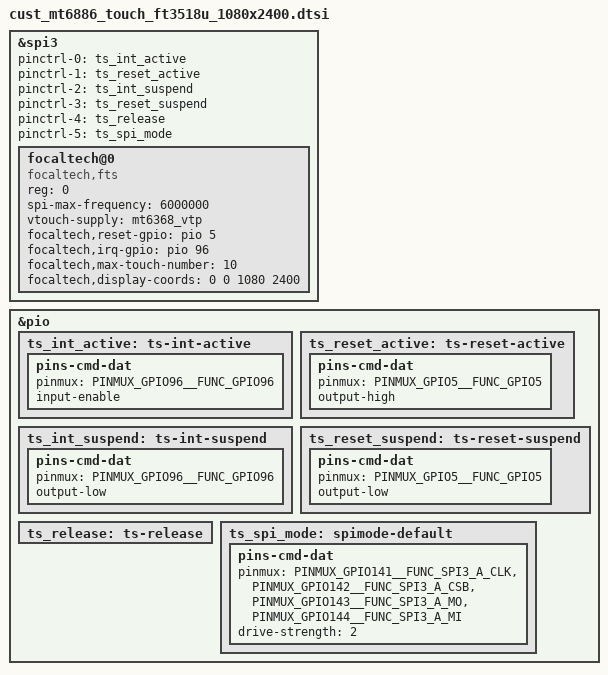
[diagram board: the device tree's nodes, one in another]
// SPDX-License-Identifier: (GPL-2.0 OR MIT)
/*
 * Copyright (C) 2020 MediaTek Inc.
 */

/*TOUCH begin*/
&spi3 {
	status = "okay";
	#address-cells = <1>;
	#size-cells = <0>;
	pinctrl-names = "pmx_ts_int_active", "pmx_ts_rst_active",
		"pmx_ts_int_suspend", "pmx_ts_rst_suspend",
		"pmx_ts_release", "ft3518u_spi_mode";
	pinctrl-0 = <&ts_int_active>;
	pinctrl-1 = <&ts_reset_active>;
	pinctrl-2 = <&ts_int_suspend>;
	pinctrl-3 = <&ts_reset_suspend>;
	pinctrl-4 = <&ts_release>;
	pinctrl-5 = <&ts_spi_mode>;

	focaltech@0 {
		status = "okay";
		compatible = "focaltech,fts";
		reg = <0>;
		spi-max-frequency = <6000000>;
		vtouch-supply = <&mt6368_vtp>;
		focaltech,reset-gpio = <&pio 5 0x0>;
		focaltech,irq-gpio = <&pio 96 0x0>;
		focaltech,max-touch-number = <10>;
		focaltech,display-coords = <0 0 1080 2400>;
	};

};

&pio {
	ts_int_active: ts-int-active {
		pins-cmd-dat {
			pinmux = <PINMUX_GPIO96__FUNC_GPIO96>;
			input-enable;
		};
	};

	ts_reset_active: ts-reset-active {
		pins-cmd-dat {
			pinmux = <PINMUX_GPIO5__FUNC_GPIO5>;
			output-high;
		};
	};

	ts_int_suspend: ts-int-suspend {
		pins-cmd-dat {
			pinmux = <PINMUX_GPIO96__FUNC_GPIO96>;
			output-low;
		};
	};

	ts_reset_suspend: ts-reset-suspend {
		pins-cmd-dat {
			pinmux = <PINMUX_GPIO5__FUNC_GPIO5>;
			output-low;
		};
	};

	ts_release: ts-release {
	};

	ts_spi_mode: spimode-default {
		pins-cmd-dat {
			pinmux = <PINMUX_GPIO141__FUNC_SPI3_A_CLK>,
				<PINMUX_GPIO142__FUNC_SPI3_A_CSB>,
				<PINMUX_GPIO143__FUNC_SPI3_A_MO>,
				<PINMUX_GPIO144__FUNC_SPI3_A_MI>;
			drive-strength = <2>;
		};
	};

};
/*TOUCH end*/
